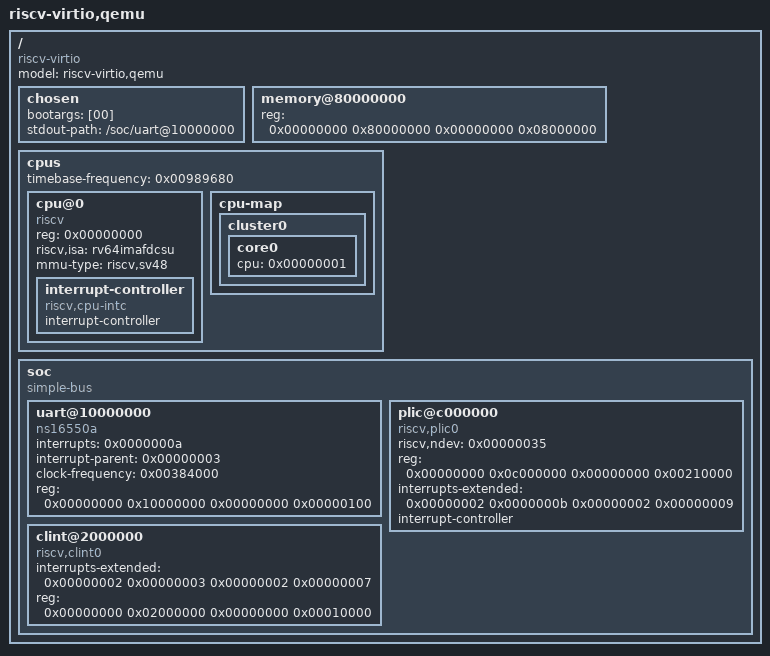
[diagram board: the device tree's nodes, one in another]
/dts-v1/;
/ {
    #address-cells = <0x00000002>;
    #size-cells = <0x00000002>;
    compatible = "riscv-virtio";
    model = "riscv-virtio,qemu";
    chosen {
        bootargs = [00];
        stdout-path = "/soc/uart@10000000";
    };
    memory@80000000 {
        device_type = "memory";
        reg = <0x00000000 0x80000000 0x00000000 0x08000000>;
    };
    cpus {
        #address-cells = <0x00000001>;
        #size-cells = <0x00000000>;
        timebase-frequency = <0x00989680>;
        cpu@0 {
            phandle = <0x00000001>;
            device_type = "cpu";
            reg = <0x00000000>;
            status = "okay";
            compatible = "riscv";
            riscv,isa = "rv64imafdcsu";
            mmu-type = "riscv,sv48";
            interrupt-controller {
                #interrupt-cells = <0x00000001>;
                interrupt-controller;
                compatible = "riscv,cpu-intc";
                phandle = <0x00000002>;
            };
        };
        cpu-map {
            cluster0 {
                core0 {
                    cpu = <0x00000001>;
                };
            };
        };
    };
    soc {
        #address-cells = <0x00000002>;
        #size-cells = <0x00000002>;
        compatible = "simple-bus";
        ranges;
        uart@10000000 {
            interrupts = <0x0000000a>;
            interrupt-parent = <0x00000003>;
            clock-frequency = <0x00384000>;
            reg = <0x00000000 0x10000000 0x00000000 0x00000100>;
            compatible = "ns16550a";
        };
        plic@c000000 {
            phandle = <0x00000003>;
            riscv,ndev = <0x00000035>;
            reg = <0x00000000 0x0c000000 0x00000000 0x00210000>;
            interrupts-extended = <0x00000002 0x0000000b 0x00000002 0x00000009>;
            interrupt-controller;
            compatible = "riscv,plic0";
            #interrupt-cells = <0x00000001>;
            #address-cells = <0x00000000>;
        };
        clint@2000000 {
            interrupts-extended = <0x00000002 0x00000003 0x00000002 0x00000007>;
            reg = <0x00000000 0x02000000 0x00000000 0x00010000>;
            compatible = "riscv,clint0";
        };
    };
};
